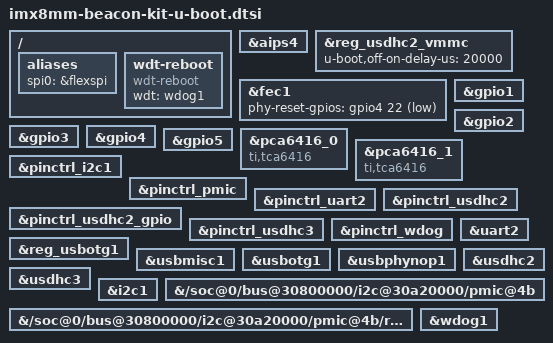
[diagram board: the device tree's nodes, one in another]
// SPDX-License-Identifier: GPL-2.0+
/*
 * Copyright 2020 Compass Electronics Group, LLC
 */

#include "imx8mm-u-boot.dtsi"

/ {
	aliases {
		spi0 = &flexspi;
	};

	wdt-reboot {
		compatible = "wdt-reboot";
		wdt = <&wdog1>;
		bootph-pre-ram;
	};
};

&aips4 {
	bootph-pre-ram;
};

&reg_usdhc2_vmmc {
	u-boot,off-on-delay-us = <20000>;
};

&fec1 {
	phy-reset-gpios = <&gpio4 22 GPIO_ACTIVE_LOW>;
};

&gpio1 {
	bootph-pre-ram;
};

&gpio2 {
	bootph-pre-ram;
};

&gpio3 {
	bootph-pre-ram;
};

&gpio4 {
	bootph-pre-ram;
};

&gpio5 {
	bootph-pre-ram;
};

&pca6416_0 {
	compatible = "ti,tca6416";
};

&pca6416_1 {
	compatible = "ti,tca6416";
};

&pinctrl_i2c1 {
	bootph-pre-ram;
};

&pinctrl_pmic {
	bootph-pre-ram;
};

&pinctrl_uart2 {
	bootph-pre-ram;
};

&pinctrl_usdhc2_gpio {
	bootph-pre-ram;
};

&pinctrl_usdhc2 {
	bootph-pre-ram;
};

&pinctrl_usdhc3 {
	bootph-pre-ram;
};

&pinctrl_wdog {
	bootph-pre-ram;
};

&reg_usbotg1 {

};

&uart2 {
	bootph-pre-ram;
};

&usbmisc1 {
	bootph-pre-ram;
};

&usbotg1 {
	bootph-pre-ram;
};

&usbphynop1 {
	bootph-pre-ram;
};

&usdhc2 {
	bootph-pre-ram;
};

&usdhc3 {
	bootph-pre-ram;
};

&i2c1 {
	bootph-pre-ram;
};

&{/soc@0/bus@30800000/i2c@30a20000/pmic@4b} {
	bootph-pre-ram;
};

&{/soc@0/bus@30800000/i2c@30a20000/pmic@4b/regulators} {
	bootph-pre-ram;
};

&wdog1 {
	bootph-pre-ram;
};
